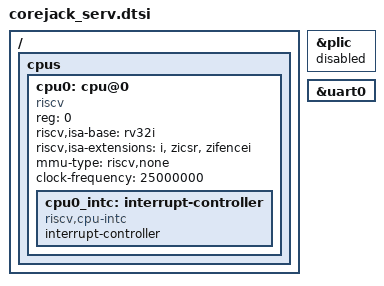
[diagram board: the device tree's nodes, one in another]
#include <corejack/corejack_rv32_common.dtsi>

/ {
	cpus {
		#address-cells = <1>;
		#size-cells = <0>;

		cpu0: cpu@0 {
			device_type = "cpu";
			compatible = "riscv";
			reg = <0>;
			riscv,isa-base = "rv32i";
			riscv,isa-extensions = "i", "zicsr", "zifencei";
			mmu-type = "riscv,none";
			status = "okay";
			clock-frequency = <25000000>;

			cpu0_intc: interrupt-controller {
				#address-cells = <0>;
				#interrupt-cells = <1>;
				compatible = "riscv,cpu-intc";
				interrupt-controller;
			};
		};
	};
};

/*
 * SERV has no machine external interrupt input (see its socket adapter), so the
 * PLIC cannot reach it: leave the PLIC out and keep the UART polled.
 */
&plic {
	status = "disabled";
};

&uart0 {
	/delete-property/ interrupt-parent;
	/delete-property/ interrupts;
};
